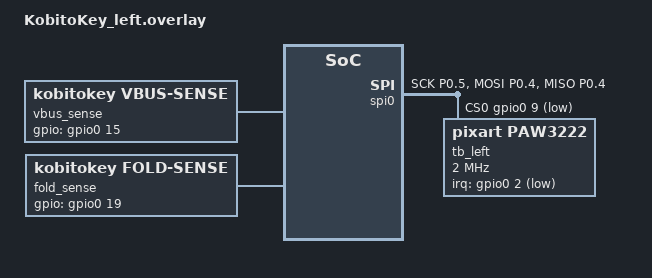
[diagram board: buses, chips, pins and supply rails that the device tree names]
#include <zephyr/dt-bindings/pinctrl/nrf-pinctrl.h>
#include "kobitokey.dtsi"
#include <input/processors.dtsi>


&pinctrl {
    spi0_default: spi0_default {
        group1 {
            psels = <NRF_PSEL(SPIM_SCK,  0, 5)>,
                    <NRF_PSEL(SPIM_MOSI, 0, 4)>,
                    <NRF_PSEL(SPIM_MISO, 0, 4)>;
        };
    };
    spi0_sleep: spi0_sleep {
        group1 {
            psels = <NRF_PSEL(SPIM_SCK,  0, 5)>,
                    <NRF_PSEL(SPIM_MOSI, 0, 4)>,
                    <NRF_PSEL(SPIM_MISO, 0, 4)>;
            low-power-enable;
        };
    };
};

&spi0 {
    status = "okay";
    compatible = "nordic,nrf-spim";
    pinctrl-0 = <&spi0_default>;
    pinctrl-1 = <&spi0_sleep>;
    pinctrl-names = "default", "sleep";
    cs-gpios = <&gpio0 9 GPIO_ACTIVE_LOW>;

    tb_left: trackball@0 {
        status = "okay";
        compatible = "pixart,paw3222";
        reg = <0>;
        spi-max-frequency = <2000000>;
        irq-gpios = <&gpio0 2 (GPIO_ACTIVE_LOW | GPIO_PULL_UP)>;
        rotation-angle = <(-25)>;
    };
};

/ {
    kobitokey_haptic_local_input: kobitokey_haptic_local_input {
        compatible = "kobitokey,haptic-local-input";
        status = "okay";
    };

    /* Same wiring as the right half, so charging and lid behaviour match. */
    vbus_sense: vbus_sense {
        compatible = "kobitokey,vbus-sense";
        status = "okay";
        gpios = <&gpio0 15 GPIO_ACTIVE_HIGH>;
    };

    fold_sense: fold_sense {
        compatible = "kobitokey,fold-sense";
        status = "okay";
        /* D12 / P0.19: Q2 makes HIGH=closed and LOW=open. */
        gpios = <&gpio0 19 GPIO_ACTIVE_HIGH>;
    };
};

&tb_left_split {
    device = <&tb_left>;
    };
